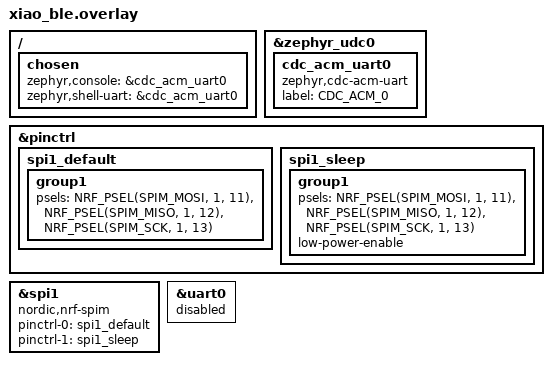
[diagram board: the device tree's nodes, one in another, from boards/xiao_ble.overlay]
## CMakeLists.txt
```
# SPDX-License-Identifier: MIT

cmake_minimum_required(VERSION 3.20.0)

find_package(Zephyr REQUIRED HINTS $ENV{ZEPHYR_BASE})
project(omi_mesh)

# Resolve image-scoped sysbuild properties as well as standalone -D arguments.
zephyr_get(OMI_FIRMWARE_VERSION SYSBUILD LOCAL)
zephyr_get(OMI_GIT_SHA SYSBUILD LOCAL)
if(NOT DEFINED OMI_FIRMWARE_VERSION)
    set(OMI_FIRMWARE_VERSION "0.0.0-dev")
endif()
if(NOT DEFINED OMI_GIT_SHA)
    execute_process(
        COMMAND git rev-parse HEAD
        WORKING_DIRECTORY "${CMAKE_CURRENT_SOURCE_DIR}"
        OUTPUT_VARIABLE OMI_GIT_SHA
        OUTPUT_STRIP_TRAILING_WHITESPACE
        ERROR_QUIET
        RESULT_VARIABLE OMI_GIT_RESULT
    )
    if(NOT OMI_GIT_RESULT EQUAL 0 OR OMI_GIT_SHA STREQUAL "")
        set(OMI_GIT_SHA "unknown")
    endif()
endif()

target_compile_definitions(app PRIVATE
    OMI_FIRMWARE_VERSION="${OMI_FIRMWARE_VERSION}"
    OMI_GIT_SHA="${OMI_GIT_SHA}"
)

target_sources(app PRIVATE
    src/main.c
    src/esb_radio.c
    src/tdma.c
    src/uart_bridge.c
    src/mesh_protocol.c
    src/mesh_protocol_rx.c
    src/mesh_protocol_runtime.c
    src/mesh_protocol_membership.c
    src/mesh_protocol_audio.c
    src/mesh_protocol_adaptive.c
    src/mesh_protocol_tx.c
    src/ws_sync.c
    ../shared/audio_bundle.c
    ../shared/bridge_frame.c
    ../shared/mesh_core.c
    ../shared/mesh_membership.c
    ../shared/mesh_adaptive.c
)

target_include_directories(app PRIVATE
    ${CMAKE_CURRENT_SOURCE_DIR}/include
    ${CMAKE_CURRENT_SOURCE_DIR}/../shared
)
```

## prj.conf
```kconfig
# OMI Mesh Firmware - Zephyr Configuration
# Target: Seeed XIAO nRF52840

# Clock Configuration - Use 32.768 kHz Crystal for low drift (~20 ppm)
CONFIG_CLOCK_CONTROL_NRF_K32SRC_XTAL=y
CONFIG_CLOCK_CONTROL_NRF_K32SRC_RC=n
# RC calibration not needed with crystal
# CONFIG_CLOCK_CONTROL_NRF_K32SRC_RC_CALIBRATION=y
# CONFIG_CLOCK_CONTROL_NRF_CALIBRATION_LF_ALWAYS_ON=y
# CONFIG_CLOCK_CONTROL_NRF_CALIBRATION_PERIOD=1000

# Enable ESB (Enhanced ShockBurst)
CONFIG_ESB=y
CONFIG_ESB_MAX_PAYLOAD_LENGTH=252

# SPI for bridge to ESP32-S3
CONFIG_SPI=y
CONFIG_SPI_NRFX=y

# UART still needed for USB CDC console
CONFIG_SERIAL=y
CONFIG_UART_INTERRUPT_DRIVEN=y

# Timers
CONFIG_COUNTER=y
CONFIG_NRFX_TIMER=y

# GPIOTE + GPPI for I2S WS sync capture
CONFIG_NRFX_GPIOTE=y
CONFIG_NRFX_GPPI=y

# System
CONFIG_HEAP_MEM_POOL_SIZE=4096
CONFIG_MAIN_STACK_SIZE=2048
CONFIG_SYSTEM_WORKQUEUE_STACK_SIZE=4096

# Logging
CONFIG_LOG=y
CONFIG_LOG_DEFAULT_LEVEL=3
CONFIG_LOG_BACKEND_UART=y

# Debug/fault handling
CONFIG_DEBUG=y
CONFIG_EXCEPTION_STACK_TRACE=y
CONFIG_FAULT_DUMP=2
CONFIG_EXTRA_EXCEPTION_INFO=y

# Console on USB CDC ACM
CONFIG_CONSOLE=y
CONFIG_UART_CONSOLE=y

# USB CDC ACM Console
CONFIG_USB_DEVICE_STACK=y
CONFIG_USB_DEVICE_STACK_NEXT=n
CONFIG_USB_CDC_ACM=y
CONFIG_USB_DEVICE_PRODUCT="OMI Mesh Node"
CONFIG_USB_DEVICE_PID=0x0001
CONFIG_UART_LINE_CTRL=y
CONFIG_USB_DEVICE_INITIALIZE_AT_BOOT=n
CONFIG_USB_CDC_ACM_RINGBUF_SIZE=512


# GPIO
CONFIG_GPIO=y

# Disable unused features to save space
CONFIG_BT=n

# Treat warnings as warnings, not errors (for development)
CONFIG_WARN_DEPRECATED=n
CONFIG_SYS_CLOCK_TICKS_PER_SEC=10000
```

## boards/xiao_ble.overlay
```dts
/* SPDX-License-Identifier: MIT */
/* XIAO nRF52840 Device Tree Overlay for OMI Mesh */

/ {
    chosen {
        zephyr,console = &cdc_acm_uart0;
        zephyr,shell-uart = &cdc_acm_uart0;
    };
};

&zephyr_udc0 {
    cdc_acm_uart0: cdc_acm_uart0 {
        compatible = "zephyr,cdc-acm-uart";
        label = "CDC_ACM_0";
    };
};

/* SPI pin configuration for ESP32-S3 bridge
 * XIAO Pin 6 (P1.11) = MOSI  (nRF sends -> ESP32 MOSI/GPIO10)
 * XIAO Pin 7 (P1.12) = MISO  (nRF receives <- ESP32 MISO/GPIO9)
 * XIAO Pin 8 (P1.13) = SCK   (nRF clock -> ESP32 SCK/GPIO11)
 * XIAO Pin 9 (P1.14) = CS    (nRF asserts -> ESP32 CS/GPIO12)
 */
&pinctrl {
    spi1_default: spi1_default {
        group1 {
            psels = <NRF_PSEL(SPIM_MOSI, 1, 11)>,
                    <NRF_PSEL(SPIM_MISO, 1, 12)>,
                    <NRF_PSEL(SPIM_SCK, 1, 13)>;
        };
    };

    spi1_sleep: spi1_sleep {
        group1 {
            psels = <NRF_PSEL(SPIM_MOSI, 1, 11)>,
                    <NRF_PSEL(SPIM_MISO, 1, 12)>,
                    <NRF_PSEL(SPIM_SCK, 1, 13)>;
            low-power-enable;
        };
    };
};

&spi1 {
    compatible = "nordic,nrf-spim";
    status = "okay";
    pinctrl-0 = <&spi1_default>;
    pinctrl-1 = <&spi1_sleep>;
    pinctrl-names = "default", "sleep";

    /* CS is manually controlled via GPIO — hardware CS is too fast
     * for ESP32 SPI slave to detect */
};

/* Disable UART0 - no longer used for bridge */
&uart0 {
    status = "disabled";
};
```

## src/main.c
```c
/**
 * @file main.c
 * @brief OMI Mesh Firmware Entry Point
 *
 * Initializes ESB radio, UART bridge, TDMA timing, and starts mesh protocol
 */

#include <zephyr/kernel.h>
#include <zephyr/logging/log.h>
#include <zephyr/usb/usb_device.h>

#include "esb_radio.h"
#include "mesh_protocol.h"
#include "tdma.h"
#include "uart_bridge.h"
#include "ws_sync.h"

LOG_MODULE_REGISTER(main, LOG_LEVEL_INF);

/* SPI poll cadence for ESP32 bridge */
#define SPI_POLL_MS 2

/* Dedicated SPI bridge thread to minimize main-loop jitter */
#define SPI_THREAD_STACK_SIZE 2048
#define SPI_THREAD_PRIORITY   -1

K_THREAD_STACK_DEFINE(s_spi_thread_stack, SPI_THREAD_STACK_SIZE);
static struct k_thread s_spi_thread;
static volatile uint32_t s_spi_loop_count = 0;

static void spi_bridge_thread(void *arg1, void *arg2, void *arg3)
{
    ARG_UNUSED(arg1);
    ARG_UNUSED(arg2);
    ARG_UNUSED(arg3);

    int64_t next_wake_ms = k_uptime_get();

    while (1) {
        uart_bridge_process();
        s_spi_loop_count++;

        next_wake_ms += SPI_POLL_MS;
        int64_t now_ms = k_uptime_get();
        int32_t sleep_ms = (int32_t)(next_wake_ms - now_ms);

        if (sleep_ms > 0) {
            k_sleep(K_MSEC(sleep_ms));
        } else {
            if (sleep_ms < -20) {
                next_wake_ms = now_ms;
            }
            k_yield();
        }
    }
}

int main(void)
{
    int ret;

    /* Initialize UART bridge FIRST - must be ready before ESP32 sends probe.
     * ESP32 sends PING within ~200ms of boot, so this must happen immediately. */
    int bridge_ret = uart_bridge_init();

    /* Enable USB subsystem for logging (works even without a USB host) */
    ret = usb_enable(NULL);
    if (ret != 0 && ret != -EALREADY) {
        return ret;
    }

    /* Short delay for USB CDC enumeration before first output */
    k_sleep(K_MSEC(1000));

    printk("\n\n*** OMI Mesh Firmware booted ***\n\n");
    printk("Firmware version: %s\n", OMI_FIRMWARE_VERSION);
    printk("Git SHA: %s\n", OMI_GIT_SHA);

    if (bridge_ret != 0 && bridge_ret != -EALREADY) {
        printk("[DIAG] UART bridge init FAILED: %d\n", bridge_ret);
        return bridge_ret;
    }

    if (!uart_bridge_is_initialized()) {
        printk("[DIAG] UART bridge init FAILED\n");
    } else {
        printk("[DIAG] UART bridge init OK\n");
    }

    /* Initialize ESB radio */
    printk("[DIAG] Initializing ESB radio...\n");
    ret = esb_radio_init(mesh_channel_esb_rf(MESH_CHANNEL_DEFAULT));
    if (ret) {
        printk("[DIAG] ESB radio init FAILED: %d\n", ret);
        return ret;
    }
    printk("[DIAG] ESB radio OK\n");

    /* Initialize TDMA timing */
    printk("[DIAG] Initializing TDMA...\n");
    ret = tdma_init();
    if (ret) {
        printk("[DIAG] TDMA init FAILED: %d\n", ret);
        return ret;
    }
    printk("[DIAG] TDMA OK\n");

    /* Initialize WS sync capture diagnostics */
    printk("[DIAG] Initializing WS sync capture...\n");
    ret = ws_sync_init();
    if (ret) {
        printk("[DIAG] WS sync init FAILED: %d (continuing without sync)\n", ret);
    } else {
        printk("[DIAG] WS sync OK\n");
        ws_sync_start();
    }

    /* Initialize mesh protocol */
    printk("[DIAG] Initializing mesh protocol...\n");
    ret = mesh_protocol_init();
    if (ret) {
        printk("[DIAG] Mesh protocol init FAILED: %d\n", ret);
        return ret;
    }
    printk("[DIAG] Mesh protocol OK\n");

    /* NOTE: Don't start mesh automatically - wait for ESP32 command.
     * This allows both boards to be ready before mesh discovery starts,
     * ensuring proper coordinator election. */
    printk("[DIAG] Mesh initialized, waiting for ESP32 enable command\n");

    /* Start dedicated SPI polling thread and let main loop stay lightweight */
    k_thread_create(&s_spi_thread, s_spi_thread_stack, K_THREAD_STACK_SIZEOF(s_spi_thread_stack),
                    spi_bridge_thread, NULL, NULL, NULL, SPI_THREAD_PRIORITY, 0, K_NO_WAIT);
    printk("[DIAG] Entering main loop (SPI thread active)\n");

    uint32_t loop_count = 0;
    while (1) {
        loop_count++;
        if (loop_count % 100 == 0) {
            printk("."); /* Quick heartbeat every 10 seconds */
        }
        if (loop_count % 300 == 0) {
            printk("\n[DIAG] heartbeat: main=%u spi=%u\n", loop_count, s_spi_loop_count);
        }

        /* Sleep to let other tasks run */
        k_sleep(K_MSEC(100));
    }

    return 0;
}
```

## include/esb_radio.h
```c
/**
 * @file esb_radio.h
 * @brief ESB Radio Driver for OMI Mesh
 */

#ifndef OMI_ESB_RADIO_H
#define OMI_ESB_RADIO_H

#include <stdbool.h>
#include <stdint.h>

/**
 * @brief Callback for received ESB packets
 */
typedef void (*esb_rx_callback_t)(const uint8_t *data, uint8_t len, const uint8_t *src_addr,
                                  int8_t rssi);

typedef struct {
    uint32_t tx_count;
    uint32_t tx_timeout_count;
    uint32_t tx_busy_count;
    uint32_t tx_write_fail_count;
    uint32_t tx_failed_event_count;
    uint32_t tx_wait_us_avg;
    uint32_t tx_wait_us_max;
    uint32_t rx_pause_us_avg;
    uint32_t rx_pause_us_max;
    uint32_t rx_no_callback_count;
    uint32_t rx_flush_drop_count;
    uint32_t rx_restart_fail_count;
} esb_radio_timing_stats_t;

/**
 * @brief Initialize ESB radio
 * @param channel RF channel (0-100)
 * @return 0 on success, negative error code on failure
 */
int esb_radio_init(uint8_t channel);

/** Set RF channel only while initialized and RX/TX stopped; retain it for role reinitialization. */
int esb_radio_set_channel(uint8_t channel);

/**
 * @brief Deinitialize ESB radio
 */
void esb_radio_deinit(void);

/**
 * @brief Set RX callback
 */
void esb_radio_set_rx_callback(esb_rx_callback_t cb);

/**
 * @brief Send packet via ESB (broadcast)
 * @param data Packet data
 * @param len Data length (max 252 bytes)
 * @return 0 on success
 */
int esb_radio_send(const uint8_t *data, uint8_t len);

/**
 * @brief Send packet to specific address
 */
int esb_radio_send_to(const uint8_t *addr, const uint8_t *data, uint8_t len);

/**
 * @brief Start RX mode
 */
int esb_radio_start_rx(void);

/**
 * @brief Stop RX mode
 */
void esb_radio_stop_rx(void);

/**
 * @brief Get local ESB address
 */
void esb_radio_get_address(uint8_t *addr);

/**
 * @brief Get ESB TX/RX timing statistics
 */
void esb_radio_get_timing_stats(esb_radio_timing_stats_t *stats);

#endif /* OMI_ESB_RADIO_H */
```

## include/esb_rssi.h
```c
#ifndef OMI_ESB_RSSI_H
#define OMI_ESB_RSSI_H

#include <stdint.h>

static inline int8_t esb_rssi_to_dbm(int16_t magnitude)
{
    /* NCS 3.4.1 ESB stores nrf_radio_rssi_sample_get() as positive magnitude. */
    return magnitude >= 1 && magnitude <= 127 ? (int8_t)-magnitude : INT8_MAX;
}

#endif /* OMI_ESB_RSSI_H */
```

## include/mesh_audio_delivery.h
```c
#ifndef OMI_MESH_AUDIO_DELIVERY_H
#define OMI_MESH_AUDIO_DELIVERY_H

#include <stdbool.h>
#include <stdint.h>

/* Compare RF ISR receipt time, not the later SPI delivery time. */
static inline bool mesh_audio_delivery_allowed(bool enabled, int64_t received_us,
                                               int64_t cutoff_us)
{
    return enabled && received_us >= cutoff_us;
}

#endif /* OMI_MESH_AUDIO_DELIVERY_H */
```

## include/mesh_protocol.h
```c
/**
 * @file mesh_protocol.h
 * @brief Shared mesh protocol definitions (matching ESP32-S3 mesh.h)
 */

#ifndef OMI_MESH_PROTOCOL_H
#define OMI_MESH_PROTOCOL_H

#include <stdbool.h>
#include <stdint.h>

/* Shared on-air protocol definitions (single source of truth, also used by the
 * ESP-NOW build). Only nRF/ESB-specific items are defined below. */
#include "mesh_protocol_defs.h"

/* ============================================================================
 * nRF/ESB-specific protocol types
 *
 * Constants, enums (mesh_role_t / mesh_state_t / mesh_pkt_type_t), the packet
 * header, and payload structs come from shared/mesh_protocol_defs.h (included
 * above). Only nRF/ESB-specific items are defined here.
 * ============================================================================ */

/**
 * @brief SYNC payload - nRF/ESB variant (5-byte ESB address for tiebreaking)
 *
 * Not in the shared header: the coordinator address width differs from the
 * ESP-NOW build (which uses a 6-byte WiFi MAC).
 */
typedef struct __attribute__((packed)) {
    uint32_t frame_counter;
    int16_t drift_ppm;
    uint8_t coordinator_addr[5]; /* ESB address for coordinator tiebreaking */
} mesh_sync_payload_t;

typedef struct __attribute__((packed)) {
    uint8_t capabilities;
    uint8_t reserved;
    uint8_t requester_addr[5];
} mesh_join_v2_payload_t;

typedef struct __attribute__((packed)) {
    uint8_t assigned_id;
    uint8_t slot_index;
    uint8_t coordinator_id;
    uint8_t target_addr[5];
} mesh_join_ack_v2_payload_t;

typedef struct __attribute__((packed)) {
    uint8_t sender_addr[5];
} mesh_leave_v2_payload_t;

_Static_assert(sizeof(mesh_sync_payload_t) == 11, "nRF SYNC wire size changed");
_Static_assert(sizeof(mesh_join_v2_payload_t) == 7, "nRF JOIN_V2 wire size changed");
_Static_assert(sizeof(mesh_join_ack_v2_payload_t) == 8, "nRF JOIN_ACK_V2 wire size changed");
_Static_assert(sizeof(mesh_leave_v2_payload_t) == 5, "nRF LEAVE identity wire size changed");

/* ============================================================================
 * Peer Info
 * ============================================================================ */

typedef struct {
    uint8_t node_id;
    uint8_t esb_addr[5]; /* ESB pipe address */
    int8_t slot_index;
    int64_t last_seen_ms;
    uint8_t battery_pct;
    int8_t rssi_dbm;
    uint8_t peer_count;
    uint8_t fw_version;
    int8_t temperature_c;
    uint8_t heard_bitmap;
    uint8_t relay_bitmap;
    bool active;
    bool announced;
} mesh_peer_info_t;

/**
 * @brief Raw audio is unsupported; use mesh_protocol_send_audio_v2() for LC3 bundles.
 * @return -ENOTSUP
 */
int mesh_protocol_send_audio(const uint8_t *data, uint8_t len, uint8_t audio_flags);

/**
 * @brief Queue a mandatory V2 microphone bundle for transmission
 */
int mesh_protocol_send_audio_v2(const uint8_t *data, uint8_t len);

void mesh_protocol_request_start(uint8_t generation, uint8_t talk_channel);
void mesh_protocol_request_stop(uint8_t generation);
void mesh_protocol_request_audio_pause(uint8_t generation);
void mesh_protocol_request_audio_resume(uint8_t generation);
void mesh_protocol_request_status(void);

/**
 * @brief Initialize mesh protocol
 * @return 0 on success
 */
int mesh_protocol_init(void);

/**
 * @brief Start mesh protocol (scan/join/host)
 * @return 0 on success
 */
int mesh_protocol_start(void);

/**
 * @brief Stop mesh protocol
 */
void mesh_protocol_stop(void);

/**
 * @brief Get current mesh state
 * @return Current state (IDLE, SCANNING, JOINING, ACTIVE)
 */
mesh_state_t mesh_protocol_get_state(void);

/**
 * @brief Get current mesh role
 * @return Current role (NONE, COORDINATOR, PARTICIPANT)
 */
mesh_role_t mesh_protocol_get_role(void);

/**
 * @brief Get current node ID
 * @return Node ID (0 if not joined)
 */
uint8_t mesh_protocol_get_node_id(void);

/**
 * @brief Get current peer count
 * @return Number of active peers
 */
uint8_t mesh_protocol_get_peer_count(void);

#endif /* OMI_MESH_PROTOCOL_H */
```

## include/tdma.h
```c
/**
 * @file tdma.h
 * @brief TDMA Frame Timing for OMI Mesh
 */

#ifndef OMI_TDMA_H
#define OMI_TDMA_H

#include <stdbool.h>
#include <stdint.h>

/**
 * @brief Callback for slot timing events
 */
typedef void (*tdma_slot_callback_t)(uint8_t slot_index, uint32_t frame_counter);
typedef void (*tdma_control_callback_t)(uint32_t frame_counter);

typedef struct {
    uint32_t slot_due;
    uint32_t slot_submit_drop;
    uint32_t slot_late_drop;
    uint32_t control_due;
    uint32_t control_submit_drop;
    uint32_t control_late_drop;
    uint32_t discipline_due;
    uint32_t discipline_submit_drop;
    uint32_t discipline_capture_drop;
    uint32_t tune_request_count;
    uint32_t tune_clamp_count;
    uint32_t correction_apply_count;
    uint32_t skipped_frame_count;
    uint32_t sync_acquire_count;
    uint32_t sync_reacquire_count;
    uint32_t sync_history_miss_count;
    int64_t correction_applied_us;
    int32_t correction_pending_us;
    int32_t last_correction_us;
    int32_t sync_frame_diff;
    int32_t sync_phase_correction_us;
    uint32_t commanded_period_us;
    uint32_t measured_interval_us;
    int16_t remote_rate_ppm;
    bool remote_rate_valid;
    int32_t callback_jitter_us;
    uint32_t callback_jitter_max_us;
} tdma_stats_t;

/**
 * @brief Initialize TDMA timing
 * @return 0 on success
 */
int tdma_init(void);

/**
 * @brief Start TDMA frame timer
 * @param slot_index Assigned slot (0-7)
 */
int tdma_start(int8_t slot_index, bool synchronized);

/**
 * @brief Stop TDMA timing
 */
void tdma_stop(void);

/**
 * @brief Set slot callback (called when it's our TX slot)
 */
void tdma_set_slot_callback(tdma_slot_callback_t cb);
void tdma_set_control_callback(tdma_control_callback_t cb);
void tdma_set_slot_index(int8_t slot_index);
void tdma_get_stats(tdma_stats_t *stats);

/**
 * @brief Get current frame counter
 */
uint32_t tdma_get_frame_counter(void);
bool tdma_clock_snapshot(uint32_t *frame, uint16_t *phase_us);
void tdma_set_clock_source(bool local);

/**
 * @brief Get microseconds until our TX slot
 */
int32_t tdma_get_time_to_slot_us(void);

/**
 * @brief Get usable microseconds remaining before the guarded TX deadline
 * @return Remaining usable time, or 0 when outside an active local slot
 */
uint32_t tdma_get_current_slot_remaining_us(void);

/**
 * @brief Synchronize to coordinator timing
 * @param frame_counter Coordinator's frame counter
 * @param drift_ppm Initial fallback correction in ppm until remote frames establish a rate.
 */
void tdma_sync(uint32_t frame_counter, int16_t drift_ppm, int64_t frame_start_us);

/**
 * @brief Queue a bounded phase correction for upcoming frame periods.
 * @param offset_us Positive stretches upcoming periods; negative shortens them.
 */
void tdma_tune_timing(int32_t offset_us);

#endif /* OMI_TDMA_H */
```

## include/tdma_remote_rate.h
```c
#ifndef OMI_TDMA_REMOTE_RATE_H
#define OMI_TDMA_REMOTE_RATE_H

#include <stdbool.h>
#include <stdint.h>

#define TDMA_REMOTE_RATE_FRAME_US 20000U
#define TDMA_REMOTE_RATE_MAX_PPM 5000
#define TDMA_REMOTE_RATE_MAX_GAP_FRAMES 250U
#define TDMA_REMOTE_RATE_WINDOW_FRAMES 50U
#define TDMA_REMOTE_RATE_MIN_FRAMES 10U
#define TDMA_REMOTE_RATE_SAMPLES 8U

typedef struct {
    uint32_t frame;
    int64_t start_us;
} tdma_remote_rate_sample_t;

typedef struct {
    tdma_remote_rate_sample_t samples[TDMA_REMOTE_RATE_SAMPLES];
    tdma_remote_rate_sample_t last;
    uint8_t count;
    bool seen;
    bool valid;
    int16_t ppm;
} tdma_remote_rate_t;

static inline void tdma_remote_rate_reset(tdma_remote_rate_t *rate)
{
    rate->count = 0;
    rate->seen = false;
    rate->valid = false;
    rate->ppm = 0;
}

/* Returns true once at least ten remote frames have supplied a rate estimate.
 * Invalid/stale observations do not perturb the last good estimate. */
static inline bool tdma_remote_rate_observe(tdma_remote_rate_t *rate, uint32_t frame,
                                             int64_t start_us)
{
    if (rate->seen) {
        tdma_remote_rate_sample_t last = rate->last;
        uint32_t frames = frame - last.frame;
        if (!frames || frames >= UINT32_C(0x80000000)) return rate->valid;
        if (start_us <= last.start_us) return rate->valid;
        if (frames > TDMA_REMOTE_RATE_MAX_GAP_FRAMES) {
            tdma_remote_rate_reset(rate);
        } else {
            uint64_t elapsed = (uint64_t)start_us - (uint64_t)last.start_us;
            uint64_t expected = (uint64_t)frames * TDMA_REMOTE_RATE_FRAME_US;
            uint64_t tolerance = expected * TDMA_REMOTE_RATE_MAX_PPM / 1000000U + 300U;
            if (elapsed < expected - tolerance || elapsed > expected + tolerance)
                return rate->valid;
        }
    }

    rate->last = (tdma_remote_rate_sample_t){frame, start_us};
    rate->seen = true;
    /* Sample at most every ten frames so frequent SYNCs retain a useful window. */
    if (rate->count && frame - rate->samples[rate->count - 1U].frame <
        TDMA_REMOTE_RATE_MIN_FRAMES) return rate->valid;

    /* Retain a rolling ~1 s baseline without losing a first 30-frame relay interval. */
    while (rate->count >= 2U &&
           frame - rate->samples[1].frame >= TDMA_REMOTE_RATE_WINDOW_FRAMES) {
        for (uint8_t i = 1; i < rate->count; i++) rate->samples[i - 1U] = rate->samples[i];
        rate->count--;
    }
    if (rate->count == TDMA_REMOTE_RATE_SAMPLES) {
        for (uint8_t i = 1; i < rate->count; i++) rate->samples[i - 1U] = rate->samples[i];
        rate->count--;
    }
    rate->samples[rate->count++] = (tdma_remote_rate_sample_t){frame, start_us};
    uint32_t frames = frame - rate->samples[0].frame;
    if (frames >= TDMA_REMOTE_RATE_MIN_FRAMES) {
        uint64_t elapsed = (uint64_t)start_us - (uint64_t)rate->samples[0].start_us;
        int64_t expected = (int64_t)frames * TDMA_REMOTE_RATE_FRAME_US;
        int64_t ppm = ((int64_t)elapsed - expected) * 1000000 / expected;
        if (ppm > TDMA_REMOTE_RATE_MAX_PPM) ppm = TDMA_REMOTE_RATE_MAX_PPM;
        if (ppm < -TDMA_REMOTE_RATE_MAX_PPM) ppm = -TDMA_REMOTE_RATE_MAX_PPM;
        rate->ppm = (int16_t)ppm;
        rate->valid = true;
    }
    return rate->valid;
}

#endif /* OMI_TDMA_REMOTE_RATE_H */
```

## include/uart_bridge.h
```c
/**
 * @file uart_bridge.h
 * @brief SPI Bridge to ESP32-S3 (nRF52840 = SPI Master)
 *
 * "uart_bridge" naming retained for API compatibility with
 * existing callers (main.c, mesh_protocol.c).
 */

#ifndef OMI_UART_BRIDGE_H
#define OMI_UART_BRIDGE_H

#include <stdbool.h>
#include <stdint.h>

#include "bridge_protocol_defs.h"

#define UART_PKT_AUDIO    BRIDGE_PKT_AUDIO
#define UART_PKT_AUDIO_V2 BRIDGE_PKT_AUDIO_V2
#define UART_PKT_STATUS   BRIDGE_PKT_STATUS
#define UART_PKT_EVENT    BRIDGE_PKT_MESH_EVENT
#define UART_PKT_COMMAND  BRIDGE_PKT_CONTROL
#define UART_PKT_LOG      BRIDGE_PKT_LOG

/* Packet sync byte */
#define UART_SYNC_BYTE 0xAA

/* SPI master poll interval (ms) */
#define BRIDGE_SPI_POLL_INTERVAL_MS 5

/* Max transfer size - must match ESP32 slave */
#define BRIDGE_SPI_MAX_XFER 256

/* Hardware ACK line: nRF XIAO D10 (P1.15) -> ESP32 XIAO D1 (GPIO2) */
#define BRIDGE_ACK_PORT 1
#define BRIDGE_ACK_PIN  15

/**
 * @brief Initialize SPI bridge (master mode)
 * @return 0 on success
 */
int uart_bridge_init(void);

/**
 * @brief Send an intact V2 audio bundle to ESP32 with its source ID prefix
 */
int uart_bridge_send_audio_v2(uint8_t src_id, const uint8_t *data, uint8_t len);

/** Drop queued outbound audio at a mesh stop boundary. */
void uart_bridge_discard_pending_audio(void);

/** Drop queued playback and gate RF-to-local playback until resumed. */
void uart_bridge_set_audio_delivery_enabled(bool enabled);

/**
 * @brief Send mesh event to ESP32
 * @param event_type Event type
 * @param data Optional event data
 * @param len Data length
 * @return 0 on success
 */
int uart_bridge_send_event(uint8_t event_type, const uint8_t *data, uint8_t len);

/**
 * @brief Send mesh status to ESP32
 * @param role Current role
 * @param peer_count Number of peers
 * @param node_id Local node ID
 */
int uart_bridge_send_status(uint8_t state, uint8_t role, uint8_t peer_count, uint8_t node_id,
                            int8_t slot_index, uint8_t coordinator_id);

int uart_bridge_send_command_ack(uint8_t command, uint8_t generation, int result);

/**
 * @brief Process incoming SPI data (call from main loop)
 *
 * Performs one full-duplex SPI transaction: sends any queued TX packet
 * while simultaneously receiving from the ESP32 slave.
 */
void uart_bridge_process(void);

/**
 * @brief Check if SPI bridge is initialized
 * @return true if initialized
 */
bool uart_bridge_is_initialized(void);

/**
 * @brief Send debug log message to ESP32
 * @param msg Log message string
 * @param len Length of message (max 250 bytes)
 * @return 0 on success
 */
int uart_bridge_send_log(const char *msg, uint8_t len);

#endif /* OMI_UART_BRIDGE_H */
```

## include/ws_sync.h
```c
/**
 * @file ws_sync.h
 * @brief I2S Word-Select (WS) Sync Capture
 *
 * Captures the ESP32-S31's physical 48 kHz I2S WS signal on nRF GPIO P0.02
 * (XIAO D0) using GPIOTE + PPI + TIMER1 for clock diagnostics. This is not the
 * 16 kHz Opus mesh audio rate. RF TDMA timing remains on a fixed 20 ms cadence.
 */

#ifndef OMI_WS_SYNC_H
#define OMI_WS_SYNC_H

#include <stdbool.h>
#include <stdint.h>

/**
 * @brief Initialize WS sync capture hardware (GPIOTE + PPI + TIMER1).
 * @return 0 on success, negative errno on failure.
 */
int ws_sync_init(void);

/**
 * @brief Start capturing WS edges.
 */
void ws_sync_start(void);

/**
 * @brief Stop capturing WS edges.
 */
void ws_sync_stop(void);

/**
 * @brief Capture the WS edge counter at a TDMA boundary.
 *
 * This is safe to call from the frame timer ISR. The caller must keep the
 * returned count paired with that frame's sequence number.
 */
bool ws_sync_capture(uint32_t *edge_count);

/**
 * @brief Process a captured WS edge count for diagnostics.
 *
 * Process each frame-boundary capture from deferred context. Returns the
 * measured timing difference in microseconds.
 *
 * @param frame_counter Frame sequence paired with edge_count at capture time.
 * @param edge_count Absolute WS edge count captured at the frame boundary.
 * @param[out] correction_us  Signed correction: positive = nRF frame
 *             was too fast (stretch it), negative = too slow (shrink it).
 * @return true if a valid measurement was produced, false if not enough
 *         data yet (e.g. first call, or WS signal absent).
 */
bool ws_sync_sample(uint32_t frame_counter, uint32_t edge_count, int32_t *correction_us);

typedef struct {
    uint32_t total_edges;
    uint32_t sample_count;
    uint32_t valid_count;
    uint32_t no_signal_count;
    uint32_t rejected_count;
    uint32_t last_delta_edges;
    int32_t last_correction_us;
    int32_t cumulative_drift_us;
} ws_sync_diag_t;

/**
 * @brief Get diagnostic counters for logging.
 */
void ws_sync_get_diag(ws_sync_diag_t *diag);

#endif /* OMI_WS_SYNC_H */
```

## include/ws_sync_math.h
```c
#ifndef OMI_WS_SYNC_MATH_H
#define OMI_WS_SYNC_MATH_H

#include <stdbool.h>
#include <stdint.h>

#define WS_SYNC_EXPECTED_EDGES_PER_FRAME 960U
#define WS_SYNC_MAX_ELAPSED_FRAMES 50U

typedef enum {
    WS_SYNC_MATH_INVALID,
    WS_SYNC_MATH_NO_SIGNAL,
    WS_SYNC_MATH_VALID,
} ws_sync_math_result_t;

static inline ws_sync_math_result_t ws_sync_calculate_correction(uint32_t delta,
                                                                 uint32_t elapsed_frames,
                                                                 int32_t *error_us,
                                                                 int32_t *correction_us)
{
    if (elapsed_frames == 0U || elapsed_frames > WS_SYNC_MAX_ELAPSED_FRAMES) {
        return WS_SYNC_MATH_INVALID;
    }
    if (delta == 0U) {
        return WS_SYNC_MATH_NO_SIGNAL;
    }

    uint32_t expected = elapsed_frames * WS_SYNC_EXPECTED_EDGES_PER_FRAME;
    if (delta < (expected * 3U) / 4U || delta > (expected * 5U) / 4U) {
        return WS_SYNC_MATH_INVALID;
    }

    int64_t numerator = ((int64_t)expected - (int64_t)delta) * 125;
    int64_t rounded = numerator >= 0 ? (numerator + 3) / 6 : (numerator - 3) / 6;
    *error_us = (int32_t)rounded;

    int32_t correction = *error_us / 4;
    if (correction > 500) {
        correction = 500;
    } else if (correction < -500) {
        correction = -500;
    }
    *correction_us = correction;
    return WS_SYNC_MATH_VALID;
}

#endif
```

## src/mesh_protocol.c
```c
/**
 * @file mesh_protocol.c
 * @brief Mesh protocol facade: shared context singleton and public accessors
 *
 * Module ownership: mesh_protocol_rx.c (ESB receive handoff),
 * mesh_protocol_membership.c (join/election/peers), mesh_protocol_audio.c
 * (audio ingress/relay/slot TX), mesh_protocol_tx.c (control/packet egress),
 * mesh_protocol_runtime.c (lifecycle, command coalescing, status work).
 *
 * NOTE: The system workqueue owns all mesh protocol state. SPI commands are
 * coalesced atomically, audio is copied through a message queue, and timer or
 * radio ISR paths only submit work or publish into protected rings.
 */

#include "mesh_protocol.h"

#include <zephyr/logging/log.h>

#include "mesh_protocol_internal.h"

LOG_MODULE_REGISTER(mesh, LOG_LEVEL_INF);

/* Version 4 is a fail-closed RF migration: older peers have no talk group. */
_Static_assert(MESH_PACKET_PAYLOAD_MAX == 200, "mesh payload capacity changed");
_Static_assert(MESH_PACKET_OUTER_MAX == 209, "mesh packet capacity changed");
_Static_assert(MESH_PACKET_OUTER_MAX <= UINT8_MAX, "ESB packet length no longer fits uint8_t");

static mesh_protocol_context_t s_context = {
    .state = MESH_STATE_IDLE,
    .role = MESH_ROLE_NONE,
    .slot_index = -1,
    .talk_channel = MESH_CHANNEL_DEFAULT,
};

mesh_protocol_context_t *mesh_protocol_context_get(void)
{
    return &s_context;
}

mesh_state_t mesh_protocol_get_state(void)
{
    return s_context.state;
}

mesh_role_t mesh_protocol_get_role(void)
{
    return s_context.role;
}

uint8_t mesh_protocol_get_node_id(void)
{
    return s_context.node_id;
}

uint8_t mesh_protocol_get_peer_count(void)
{
    return s_context.peer_count;
}
```
